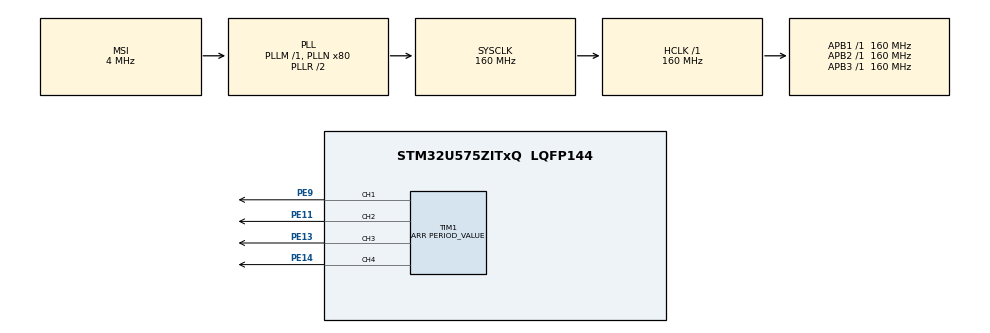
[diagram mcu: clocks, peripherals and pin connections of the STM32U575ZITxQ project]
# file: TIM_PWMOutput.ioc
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CORTEX_M33_NS.userName=CORTEX_M33
Mcu.Family=STM32U5
Mcu.Name=STM32U575ZITxQ
Mcu.Package=LQFP144
NVIC.PriorityGroup=NVIC_PRIORITYGROUP_4
PE11.GPIO_PuPd=GPIO_NOPULL
PE11.GPIO_Speed=GPIO_SPEED_FREQ_VERY_HIGH
PE11.Signal=S_TIM1_CH2
PE13.GPIO_PuPd=GPIO_NOPULL
PE13.GPIO_Speed=GPIO_SPEED_FREQ_VERY_HIGH
PE13.Signal=S_TIM1_CH3
PE14.GPIO_PuPd=GPIO_NOPULL
PE14.GPIO_Speed=GPIO_SPEED_FREQ_VERY_HIGH
PE14.Signal=S_TIM1_CH4
PE9.GPIO_PuPd=GPIO_NOPULL
PE9.GPIO_Speed=GPIO_SPEED_FREQ_VERY_HIGH
PE9.Signal=S_TIM1_CH1
PWR.PowerMode=PWR_SMPS_SUPPLY
ProjectManager.HeapSize=0x200
ProjectManager.StackSize=0x400
ProjectManager.TargetToolchain=EWARM V8.32
RCC.ADCFreq_Value=16000000
RCC.AHBFreq_Value=160000000
RCC.APB1Freq_Value=160000000
RCC.APB1TimFreq_Value=160000000
RCC.APB2Freq_Value=160000000
RCC.APB2TimFreq_Value=160000000
RCC.APB3Freq_Value=160000000
RCC.CortexFreq_Value=160000000
RCC.DACCLockSelectionVirtual=RCC_DAC1CLKSOURCE_LSI
RCC.DACCLockSelectionVirtualString=RCC_DAC1CLKSOURCE_LSI
RCC.EPOD_VALUE=4000000
RCC.HCLKFreq_Value=160000000
RCC.HSE_VALUE=16000000
RCC.HSI48_VALUE=48000000
RCC.HSI_VALUE=16000000
RCC.LSE_VALUE=32768
RCC.LSIDIV_VALUE=32000
RCC.MSI_VALUE=4000000
RCC.PLLN=80
RCC.SYSCLKFreq_VALUE=160000000
RCC.SYSCLKSource=RCC_SYSCLKSOURCE_PLLCLK
RCC.USBFreq_Value=48000000
RCC.VCOOutputFreq_Value=320000000
SH.S_TIM1_CH1.0=TIM1_CH1,PWM Generation1 CH1
SH.S_TIM1_CH2.0=TIM1_CH2,PWM Generation2 CH2
SH.S_TIM1_CH3.0=TIM1_CH3,PWM Generation3 CH3
SH.S_TIM1_CH4.0=TIM1_CH4,PWM Generation4 CH4
TIM1.AutoReloadPreload=TIM_AUTORELOAD_PRELOAD_DISABLE
TIM1.AutomaticOutput=TIM_AUTOMATICOUTPUT_DISABLE
TIM1.Break2Filter=0
TIM1.Break2Polarity=TIM_BREAK2POLARITY_HIGH
TIM1.Break2State=TIM_BREAK2_DISABLE
TIM1.BreakFilter=0
TIM1.BreakPolarity=TIM_BREAKPOLARITY_HIGH
TIM1.BreakState=TIM_BREAK_DISABLE
TIM1.Channel-PWM\ Generation1\ CH1=TIM_CHANNEL_1
TIM1.Channel-PWM\ Generation2\ CH2=TIM_CHANNEL_2
TIM1.Channel-PWM\ Generation3\ CH3=TIM_CHANNEL_3
TIM1.Channel-PWM\ Generation4\ CH4=TIM_CHANNEL_4
TIM1.ClearInputSource=TIM_CLEARINPUTSOURCE_NONE
TIM1.ClockDivision=TIM_CLOCKDIVISION_DIV1
TIM1.CounterMode=TIM_COUNTERMODE_UP
TIM1.LockLevel=TIM_LOCKLEVEL_OFF
TIM1.OC1Preload_PWM=ENABLE
TIM1.OC2Preload_PWM=ENABLE
TIM1.OC3Preload_PWM=ENABLE
TIM1.OC4Preload_PWM=ENABLE
TIM1.OCFastMode_PWM-PWM\ Generation1\ CH1=TIM_OCFAST_DISABLE
TIM1.OCFastMode_PWM-PWM\ Generation2\ CH2=TIM_OCFAST_DISABLE
TIM1.OCFastMode_PWM-PWM\ Generation3\ CH3=TIM_OCFAST_DISABLE
TIM1.OCFastMode_PWM-PWM\ Generation4\ CH4=TIM_OCFAST_DISABLE
TIM1.OCIdleState_1=TIM_OCIDLESTATE_RESET
TIM1.OCIdleState_2=TIM_OCIDLESTATE_RESET
TIM1.OCIdleState_3=TIM_OCIDLESTATE_RESET
TIM1.OCIdleState_4=TIM_OCIDLESTATE_RESET
TIM1.OCMode_PWM-PWM\ Generation1\ CH1=TIM_OCMODE_PWM1
TIM1.OCMode_PWM-PWM\ Generation2\ CH2=TIM_OCMODE_PWM1
TIM1.OCMode_PWM-PWM\ Generation3\ CH3=TIM_OCMODE_PWM1
TIM1.OCMode_PWM-PWM\ Generation4\ CH4=TIM_OCMODE_PWM1
TIM1.OCPolarity_1=TIM_OCPOLARITY_HIGH
TIM1.OCPolarity_2=TIM_OCPOLARITY_HIGH
TIM1.OCPolarity_3=TIM_OCPOLARITY_HIGH
TIM1.OCPolarity_4=TIM_OCPOLARITY_HIGH
TIM1.OffStateIDLEMode=TIM_OSSI_DISABLE
TIM1.OffStateRunMode=TIM_OSSR_DISABLE
TIM1.Period=PERIOD_VALUE
TIM1.Prescaler=PRESCALER_VALUE
TIM1.PulseNoDither_1=PULSE1_VALUE
TIM1.PulseNoDither_2=PULSE2_VALUE
TIM1.PulseNoDither_3=PULSE3_VALUE
TIM1.PulseNoDither_4=PULSE4_VALUE
TIM1.RepetitionCounter=0
TIM1.SourceBRK2COMP1=TIM_BREAKINPUTSOURCE_DISABLE
TIM1.SourceBRK2COMP2=TIM_BREAKINPUTSOURCE_DISABLE
TIM1.SourceBRK2DigInput=TIM_BREAKINPUTSOURCE_DISABLE
TIM1.SourceBRKCOMP1=TIM_BREAKINPUTSOURCE_DISABLE
TIM1.SourceBRKCOMP2=TIM_BREAKINPUTSOURCE_DISABLE
TIM1.SourceBRKDigInput=TIM_BREAKINPUTSOURCE_DISABLE
TIM1.TIM_MasterOutputTrigger=TIM_TRGO_RESET
TIM1.TIM_MasterOutputTrigger2=TIM_TRGO2_RESET
TIM1.TIM_MasterSlaveMode=TIM_MASTERSLAVEMODE_DISABLE
VP_ICACHE_VS_ICACHE.Mode=DirectMappedCache
VP_LPBAMQUEUE_VS_QUEUE.Mode=QUEUEMODE
VP_LPBAM_VS_SIG1.Mode=SmartRun
VP_LPBAM_VS_SIG4.Mode=LPDMA1
VP_PWR_VS_DBSignals.Mode=DisableDeadBatterySignals
VP_PWR_VS_LPOM.Mode=PowerOptimisation
VP_PWR_VS_SECSignals.Mode=Security/Privilege
board=custom

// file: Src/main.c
/* USER CODE BEGIN Header */
/**
  ******************************************************************************
  * @file    TIM/TIM_PWMOutput/Src/main.c
  * @author  MCD Application Team
  * @brief   This sample code shows how to use STM32U5xx TIM HAL API to generate
  *          4 signals in PWM.
  ******************************************************************************
  * @attention
  *
  * Copyright (c) 2021 STMicroelectronics.
  * All rights reserved.
  *
  * This software is licensed under terms that can be found in the LICENSE file
  * in the root directory of this software component.
  * If no LICENSE file comes with this software, it is provided AS-IS.
  *
  ******************************************************************************
  */
/* USER CODE END Header */
#include "main.h"

TIM_HandleTypeDef htim1;

void SystemClock_Config(void);
static void SystemPower_Config(void);
static void MX_GPIO_Init(void);
static void MX_ICACHE_Init(void);
static void MX_TIM1_Init(void);

int main(void)
{

  /* USER CODE BEGIN 1 */

  /* STM32U5xx HAL library initialization:
       - Configure the Flash prefetch
       - Configure the Systick to generate an interrupt each 1 msec
       - Set NVIC Group Priority to 3
       - Low Level Initialization
     */
  /* USER CODE END 1 */

  /* MCU Configuration--------------------------------------------------------*/

  /* Reset of all peripherals, Initializes the Flash interface and the Systick. */
  HAL_Init();

  /* Configure the System Power */
  SystemPower_Config();

  /* Configure the system clock */
  SystemClock_Config();

  /* USER CODE BEGIN SysInit */

  /* Configure LED3 */
  BSP_LED_Init(LED3);

  /* USER CODE END SysInit */

  /* Initialize all configured peripherals */
  MX_GPIO_Init();
  MX_ICACHE_Init();
  MX_TIM1_Init();
  /* USER CODE BEGIN 2 */

/*## Start PWM signals generation #######################################*/
  /* Start channel 1 */
  if (HAL_TIM_PWM_Start(&htim1, TIM_CHANNEL_1) != HAL_OK)
  {
    /* PWM Generation Error */
    Error_Handler();
  }
  /* Start channel 2 */
  if (HAL_TIM_PWM_Start(&htim1, TIM_CHANNEL_2) != HAL_OK)
  {
    /* PWM Generation Error */
    Error_Handler();
  }
  /* Start channel 3 */
  if (HAL_TIM_PWM_Start(&htim1, TIM_CHANNEL_3) != HAL_OK)
  {
    /* PWM generation Error */
    Error_Handler();
  }
  /* Start channel 4 */
  if (HAL_TIM_PWM_Start(&htim1, TIM_CHANNEL_4) != HAL_OK)
  {
    /* PWM generation Error */
    Error_Handler();
  }

  /* USER CODE END 2 */

  /* Infinite loop */
  while (1)
  {

  }
}

void SystemClock_Config(void)
{
  RCC_OscInitTypeDef RCC_OscInitStruct = {0};
  RCC_ClkInitTypeDef RCC_ClkInitStruct = {0};

  /** Configure the main internal regulator output voltage
  */
  if (HAL_PWREx_ControlVoltageScaling(PWR_REGULATOR_VOLTAGE_SCALE1) != HAL_OK)
  {
    Error_Handler();
  }

  /** Initializes the CPU, AHB and APB buses clocks
  */
  RCC_OscInitStruct.OscillatorType = RCC_OSCILLATORTYPE_MSI;
  RCC_OscInitStruct.MSIState = RCC_MSI_ON;
  RCC_OscInitStruct.MSICalibrationValue = RCC_MSICALIBRATION_DEFAULT;
  RCC_OscInitStruct.MSIClockRange = RCC_MSIRANGE_4;
  RCC_OscInitStruct.PLL.PLLState = RCC_PLL_ON;
  RCC_OscInitStruct.PLL.PLLSource = RCC_PLLSOURCE_MSI;
  RCC_OscInitStruct.PLL.PLLMBOOST = RCC_PLLMBOOST_DIV1;
  RCC_OscInitStruct.PLL.PLLM = 1;
  RCC_OscInitStruct.PLL.PLLN = 80;
  RCC_OscInitStruct.PLL.PLLP = 2;
  RCC_OscInitStruct.PLL.PLLQ = 2;
  RCC_OscInitStruct.PLL.PLLR = 2;
  RCC_OscInitStruct.PLL.PLLRGE = RCC_PLLVCIRANGE_0;
  RCC_OscInitStruct.PLL.PLLFRACN = 0;
  if (HAL_RCC_OscConfig(&RCC_OscInitStruct) != HAL_OK)
  {
    Error_Handler();
  }

  /** Initializes the CPU, AHB and APB buses clocks
  */
  RCC_ClkInitStruct.ClockType = RCC_CLOCKTYPE_HCLK|RCC_CLOCKTYPE_SYSCLK
                              |RCC_CLOCKTYPE_PCLK1|RCC_CLOCKTYPE_PCLK2
                              |RCC_CLOCKTYPE_PCLK3;
  RCC_ClkInitStruct.SYSCLKSource = RCC_SYSCLKSOURCE_PLLCLK;
  RCC_ClkInitStruct.AHBCLKDivider = RCC_SYSCLK_DIV1;
  RCC_ClkInitStruct.APB1CLKDivider = RCC_HCLK_DIV1;
  RCC_ClkInitStruct.APB2CLKDivider = RCC_HCLK_DIV1;
  RCC_ClkInitStruct.APB3CLKDivider = RCC_HCLK_DIV1;

  if (HAL_RCC_ClockConfig(&RCC_ClkInitStruct, FLASH_LATENCY_4) != HAL_OK)
  {
    Error_Handler();
  }
}

/**
  * @brief Power Configuration
  * @retval None
  */
static void SystemPower_Config(void)
{

  /*
   * Disable the internal Pull-Up in Dead Battery pins of UCPD peripheral
   */
  HAL_PWREx_DisableUCPDDeadBattery();

  /*
   * Switch to SMPS regulator instead of LDO
   */
  if (HAL_PWREx_ConfigSupply(PWR_SMPS_SUPPLY) != HAL_OK)
  {
    Error_Handler();
  }
}

static void MX_ICACHE_Init(void)
{

  /** Enable instruction cache in 1-way (direct mapped cache)
  */
  if (HAL_ICACHE_ConfigAssociativityMode(ICACHE_1WAY) != HAL_OK)
  {
    Error_Handler();
  }
  if (HAL_ICACHE_Enable() != HAL_OK)
  {
    Error_Handler();
  }

}

static void MX_TIM1_Init(void)
{

  TIM_MasterConfigTypeDef sMasterConfig = {0};
  TIM_OC_InitTypeDef sConfigOC = {0};
  TIM_BreakDeadTimeConfigTypeDef sBreakDeadTimeConfig = {0};

  htim1.Instance = TIM1;
  htim1.Init.Prescaler = PRESCALER_VALUE;
  htim1.Init.CounterMode = TIM_COUNTERMODE_UP;
  htim1.Init.Period = PERIOD_VALUE;
  htim1.Init.ClockDivision = TIM_CLOCKDIVISION_DIV1;
  htim1.Init.RepetitionCounter = 0;
  htim1.Init.AutoReloadPreload = TIM_AUTORELOAD_PRELOAD_DISABLE;
  if (HAL_TIM_PWM_Init(&htim1) != HAL_OK)
  {
    Error_Handler();
  }
  sMasterConfig.MasterOutputTrigger = TIM_TRGO_RESET;
  sMasterConfig.MasterOutputTrigger2 = TIM_TRGO2_RESET;
  sMasterConfig.MasterSlaveMode = TIM_MASTERSLAVEMODE_DISABLE;
  if (HAL_TIMEx_MasterConfigSynchronization(&htim1, &sMasterConfig) != HAL_OK)
  {
    Error_Handler();
  }
  sConfigOC.OCMode = TIM_OCMODE_PWM1;
  sConfigOC.Pulse = PULSE1_VALUE;
  sConfigOC.OCPolarity = TIM_OCPOLARITY_HIGH;
  sConfigOC.OCNPolarity = TIM_OCNPOLARITY_HIGH;
  sConfigOC.OCFastMode = TIM_OCFAST_DISABLE;
  sConfigOC.OCIdleState = TIM_OCIDLESTATE_RESET;
  sConfigOC.OCNIdleState = TIM_OCNIDLESTATE_RESET;
  if (HAL_TIM_PWM_ConfigChannel(&htim1, &sConfigOC, TIM_CHANNEL_1) != HAL_OK)
  {
    Error_Handler();
  }
  sConfigOC.Pulse = PULSE2_VALUE;
  if (HAL_TIM_PWM_ConfigChannel(&htim1, &sConfigOC, TIM_CHANNEL_2) != HAL_OK)
  {
    Error_Handler();
  }
  sConfigOC.Pulse = PULSE3_VALUE;
  if (HAL_TIM_PWM_ConfigChannel(&htim1, &sConfigOC, TIM_CHANNEL_3) != HAL_OK)
  {
    Error_Handler();
  }
  sConfigOC.Pulse = PULSE4_VALUE;
  if (HAL_TIM_PWM_ConfigChannel(&htim1, &sConfigOC, TIM_CHANNEL_4) != HAL_OK)
  {
    Error_Handler();
  }
  sBreakDeadTimeConfig.OffStateRunMode = TIM_OSSR_DISABLE;
  sBreakDeadTimeConfig.OffStateIDLEMode = TIM_OSSI_DISABLE;
  sBreakDeadTimeConfig.LockLevel = TIM_LOCKLEVEL_OFF;
  sBreakDeadTimeConfig.DeadTime = 0;
  sBreakDeadTimeConfig.BreakState = TIM_BREAK_DISABLE;
  sBreakDeadTimeConfig.BreakPolarity = TIM_BREAKPOLARITY_HIGH;
  sBreakDeadTimeConfig.BreakFilter = 0;
  sBreakDeadTimeConfig.BreakAFMode = TIM_BREAK_AFMODE_INPUT;
  sBreakDeadTimeConfig.Break2State = TIM_BREAK2_DISABLE;
  sBreakDeadTimeConfig.Break2Polarity = TIM_BREAK2POLARITY_HIGH;
  sBreakDeadTimeConfig.Break2Filter = 0;
  sBreakDeadTimeConfig.Break2AFMode = TIM_BREAK_AFMODE_INPUT;
  sBreakDeadTimeConfig.AutomaticOutput = TIM_AUTOMATICOUTPUT_DISABLE;
  if (HAL_TIMEx_ConfigBreakDeadTime(&htim1, &sBreakDeadTimeConfig) != HAL_OK)
  {
    Error_Handler();
  }
  HAL_TIM_MspPostInit(&htim1);

}

static void MX_GPIO_Init(void)
{

  /* GPIO Ports Clock Enable */
  __HAL_RCC_GPIOE_CLK_ENABLE();

}

void Error_Handler(void)
{
  /* USER CODE BEGIN Error_Handler_Debug */
  /* Turn LED3 on */
  BSP_LED_On(LED3);
  while(1)
  {
  }
  /* USER CODE END Error_Handler_Debug */
}
